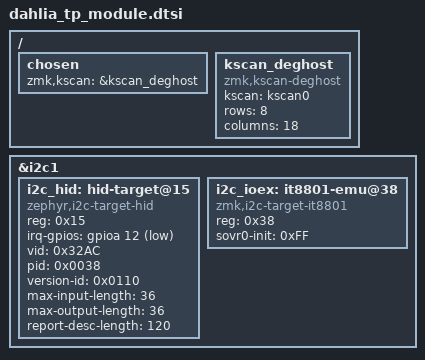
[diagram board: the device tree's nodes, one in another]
/*
 * Hardware setup for the Dahlia touchpad module.
 * The key layout comes from each shield's own files.
 */

#include <dt-bindings/zmk/matrix_transform.h>

/ {
    chosen {
        zmk,kscan = &kscan_deghost;
    };

    kscan_deghost: kscan_deghost {
        compatible = "zmk,kscan-deghost";
        kscan = <&kscan0>;
        rows = <8>;
        columns = <18>;
    };
};

/*
 * I2C HID target at address 0x15.
 * IRQ output on PA12 (active-low, open-drain).
 */
&i2c1 {
    i2c_hid: hid-target@15 {
        compatible = "zephyr,i2c-target-hid";
        reg = <0x15>;
        irq-gpios = <&gpioa 12 (GPIO_ACTIVE_LOW | GPIO_OPEN_DRAIN)>;
        vid = <0x32AC>;
        pid = <0x0038>;
        version-id = <0x0110>;
        /*
         * fw-flags = <0x01> marks a build the BIOS must not replace with
         * its bundled firmware — engineering or pinned images. Unset
         * means stock, opting into automatic updates. A flashing tool can
         * protect a stock image instead; see board.c.
         */
        max-input-length = <36>;
        max-output-length = <36>;
        report-desc-length = <120>;
    };

    /*
     * IT8801 register emulation at I2C 0x38.
     * SOVR(2) bit 0 = touchpad enable / TP_EN (drives PA15)
     * SOVR(2) bit 2 = keyboard scan enable
     * Ports 0 and 1 are unused on this device (EC-side pin
     * restrictions). SOVR shadows default to 0xFF (everything
     * enabled) so the EC sees a sane state at init.
     */
    i2c_ioex: it8801-emu@38 {
        compatible = "zmk,i2c-target-it8801";
        reg = <0x38>;
        sovr0-init = <0xFF>;
    };
};
